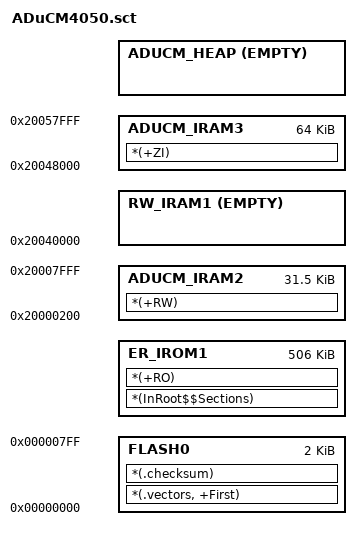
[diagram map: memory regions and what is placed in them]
;******************************************************************************
;  File: ADuCM4050.sct
;  Scatter loading file for Analog Devices ADuCM4050 processor
;
;  Copyright (c) 2011 - 2014 ARM LIMITED
;  Copyright (c) 2016 - 2017 Analog Devices, Inc.
;
;  All rights reserved.
;  Redistribution and use in source and binary forms, with or without
;  modification, are permitted provided that the following conditions are met:
;  - Redistributions of source code must retain the above copyright
;    notice, this list of conditions and the following disclaimer.
;  - Redistributions in binary form must reproduce the above copyright
;    notice, this list of conditions and the following disclaimer in the
;    documentation and/or other materials provided with the distribution.
;  - Neither the name of ARM nor the names of its contributors may be used
;    to endorse or promote products derived from this software without
;    specific prior written permission.
;
;  THIS SOFTWARE IS PROVIDED BY THE COPYRIGHT HOLDERS AND CONTRIBUTORS "AS IS"
;  AND ANY EXPRESS OR IMPLIED WARRANTIES, INCLUDING, BUT NOT LIMITED TO, THE
;  IMPLIED WARRANTIES OF MERCHANTABILITY AND FITNESS FOR A PARTICULAR PURPOSE
;  ARE DISCLAIMED. IN NO EVENT SHALL COPYRIGHT HOLDERS AND CONTRIBUTORS BE
;  LIABLE FOR ANY DIRECT, INDIRECT, INCIDENTAL, SPECIAL, EXEMPLARY, OR
;  CONSEQUENTIAL DAMAGES (INCLUDING, BUT NOT LIMITED TO, PROCUREMENT OF
;  SUBSTITUTE GOODS OR SERVICES; LOSS OF USE, DATA, OR PROFITS; OR BUSINESS
;  INTERRUPTION) HOWEVER CAUSED AND ON ANY THEORY OF LIABILITY, WHETHER IN
;  CONTRACT, STRICT LIABILITY, OR TORT (INCLUDING NEGLIGENCE OR OTHERWISE)
;  ARISING IN ANY WAY OUT OF THE USE OF THIS SOFTWARE, EVEN IF ADVISED OF THE
;  POSSIBILITY OF SUCH DAMAGE.
;******************************************************************************
LR_IROM1 0x00000000 0x0007F000 {
    FLASH0   0x00000000 0x00000800 {
        *(.vectors, +First)
        *(.checksum)
    }

    ER_IROM1 AlignExpr(ImageLimit(FLASH0), 16) 0x0007E800 {
        ; load address = execution address
        *(InRoot$$Sections)
        *(+RO)
    }

    RW_IRAM1    0x20040000 EMPTY 0 { }

    ADUCM_IRAM2 0x20000200 0x7E00  { *(+RW) }

    ADUCM_IRAM3 0x20048000 0x10000 { *(+ZI) }

    ADUCM_HEAP  AlignExpr(ImageLimit(RW_IRAM1), 16) EMPTY
        (ImageBase(ADUCM_IRAM3) - 0x2000 - AlignExpr(ImageLimit(RW_IRAM1), 16)) { } ; heap
}
